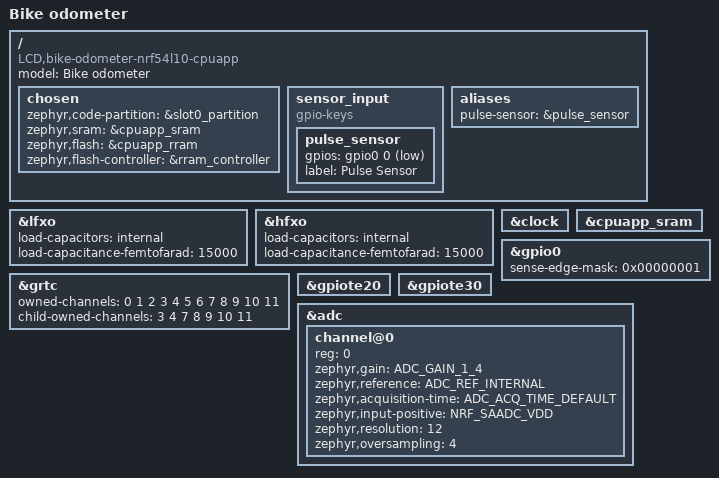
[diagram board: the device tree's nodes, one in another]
/dts-v1/;
#include <nordic/nrf54l10_cpuapp.dtsi>
#include <zephyr/dt-bindings/adc/nrf-saadc.h>
#include <zephyr/dt-bindings/adc/adc.h>
#include <zephyr/dt-bindings/gpio/gpio.h>
#include "bike-odometer-pinctrl.dtsi"

/ {
	model = "Bike odometer";
	compatible = "LCD,bike-odometer-nrf54l10-cpuapp";

	chosen {
		zephyr,code-partition = &slot0_partition;
		zephyr,sram = &cpuapp_sram;
		zephyr,flash = &cpuapp_rram;
		zephyr,flash-controller = &rram_controller;
	};

	/* Sensor input on P0.00 */
	sensor_input {
		compatible = "gpio-keys";
		pulse_sensor: pulse_sensor {
			gpios = <&gpio0 0 ( GPIO_ACTIVE_LOW)>;
			label = "Pulse Sensor";
		};
	};

	aliases {
		pulse-sensor = &pulse_sensor;
	};
};

/* 32.768 kHz external crystal (LSE) */
&lfxo {
	load-capacitors = "internal";
	load-capacitance-femtofarad = <15000>;  /* Adjust based on your crystal */
};

/* 32 MHz external crystal (HSE) */
&hfxo {
	load-capacitors = "internal";
	load-capacitance-femtofarad = <15000>;  /* Adjust based on your crystal */
};

&clock {
	status = "okay";
};

&grtc {
	owned-channels = <0 1 2 3 4 5 6 7 8 9 10 11>;
	/* Channels 7-11 reserved for Zero Latency IRQs, 3-4 for FLPR */
	child-owned-channels = <3 4 7 8 9 10 11>;
	status = "okay";
};

&cpuapp_sram {
	status = "okay";
};

&gpio0 {
	/* Use the always-on GPIO SENSE path for the Hall input so an edge on
	 * P0.00 reliably wakes the CPU while the application is parked.
	 */
	sense-edge-mask = <0x00000001>;
	status = "okay";
};

&gpiote20 {
	status = "okay";
};

&gpiote30 {
	status = "okay";
};

&adc {
	#address-cells = <1>;
	#size-cells = <0>;
	status = "okay";

	/* VDD measurement channel */
	channel@0 {
		reg = <0>;
		/* 0.9 V internal reference / 1/4 gain gives a 3.6 V VDD range. */
		zephyr,gain = "ADC_GAIN_1_4";
		zephyr,reference = "ADC_REF_INTERNAL";
		zephyr,acquisition-time = <ADC_ACQ_TIME_DEFAULT>;
		zephyr,input-positive = <NRF_SAADC_VDD>;  /* Internal VDD */
		zephyr,resolution = <12>;
		zephyr,oversampling = <4>;
	};
};

#include <nordic/nrf54l10_partition.dtsi>
